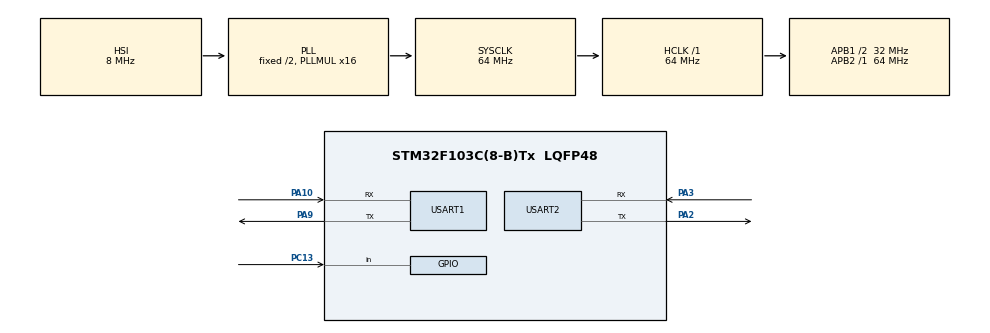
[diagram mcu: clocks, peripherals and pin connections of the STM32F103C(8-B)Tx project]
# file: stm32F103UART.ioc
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Mcu.Family=STM32F1
Mcu.Name=STM32F103C(8-B)Tx
Mcu.Package=LQFP48
NVIC.PriorityGroup=NVIC_PRIORITYGROUP_4
NVIC.USART1_IRQn=true\:0\:0\:false\:false\:true\:true\:true\:true
PA10.Mode=Asynchronous
PA10.Signal=USART1_RX
PA13.Mode=Serial_Wire
PA13.Signal=SYS_JTMS-SWDIO
PA14.Mode=Serial_Wire
PA14.Signal=SYS_JTCK-SWCLK
PA2.Mode=Asynchronous
PA2.Signal=USART2_TX
PA3.Mode=Asynchronous
PA3.Signal=USART2_RX
PA9.Mode=Asynchronous
PA9.Signal=USART1_TX
PC13-TAMPER-RTC.Signal=GPIO_Input
ProjectManager.HeapSize=0x200
ProjectManager.StackSize=0x400
ProjectManager.TargetToolchain=STM32CubeIDE
RCC.AHBFreq_Value=64000000
RCC.APB1CLKDivider=RCC_HCLK_DIV2
RCC.APB1Freq_Value=32000000
RCC.APB1TimFreq_Value=64000000
RCC.APB2Freq_Value=64000000
RCC.APB2TimFreq_Value=64000000
RCC.HCLKFreq_Value=64000000
RCC.PLLMUL=RCC_PLL_MUL16
RCC.SYSCLKFreq_VALUE=64000000
RCC.SYSCLKSource=RCC_SYSCLKSOURCE_PLLCLK
RCC.USBFreq_Value=64000000
USART1.VirtualMode=VM_ASYNC
USART2.VirtualMode=VM_ASYNC
board=custom

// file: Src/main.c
/* USER CODE BEGIN Header */
/**
  ******************************************************************************
  * @file           : main.c
  * @brief          : Main program body
  ******************************************************************************
  * @attention
  *
  * Copyright (c) 2023 STMicroelectronics.
  * All rights reserved.
  *
  * This software is licensed under terms that can be found in the LICENSE file
  * in the root directory of this software component.
  * If no LICENSE file comes with this software, it is provided AS-IS.
  *
  ******************************************************************************
  */

/* USER CODE END Header */
#include "main.h"

/* USER CODE BEGIN PTD */

#define BUFFER_SIZE 16

uint8_t buffer[BUFFER_SIZE] = {0,};
ring_buffer_t rx_buffer;

/* USER CODE END PTD */

UART_HandleTypeDef huart1;
UART_HandleTypeDef huart2;

void SystemClock_Config(void);
static void MX_GPIO_Init(void);
static void MX_USART1_UART_Init(void);
static void MX_USART2_UART_Init(void);

/* USER CODE BEGIN 0 */
/**
 * @brief processing interrupts to receive data
 */

/* USER CODE END 0 */

int main(void)
{

  /* MCU Configuration--------------------------------------------------------*/

  /* Reset of all peripherals, Initializes the Flash interface and the Systick. */
  HAL_Init();

  /* Configure the system clock */
  SystemClock_Config();

  /* Initialize all configured peripherals */
  MX_GPIO_Init();
  MX_USART1_UART_Init();
  MX_USART2_UART_Init();

  /* Infinite loop */
  /* USER CODE BEGIN WHILE */
    ring_buffer_init(buffer, BUFFER_SIZE, &rx_buffer); /// initialization before processing buffer

    while (1) {

    /* USER CODE END WHILE */

    /* USER CODE BEGIN 3 */
        uint8_t rx_temp_byte;
        HAL_UART_Receive(&huart1, &rx_temp_byte, 1, 1000);
        ring_buffer_put(rx_temp_byte, &rx_buffer);
        uint8_t tx_temp_byte;
        tx_temp_byte = ring_buffer_get(&rx_buffer);
        HAL_UART_Transmit(&huart1, &tx_temp_byte, 1, 1000);

       // HAL_UART_Receive_IT(&huart1, &temp_data, 1);

    }
  /* USER CODE END 3 */
}

void SystemClock_Config(void)
{
  RCC_OscInitTypeDef RCC_OscInitStruct = {0};
  RCC_ClkInitTypeDef RCC_ClkInitStruct = {0};

  /** Initializes the RCC Oscillators according to the specified parameters
  * in the RCC_OscInitTypeDef structure.
  */
  RCC_OscInitStruct.OscillatorType = RCC_OSCILLATORTYPE_HSI;
  RCC_OscInitStruct.HSIState = RCC_HSI_ON;
  RCC_OscInitStruct.HSICalibrationValue = RCC_HSICALIBRATION_DEFAULT;
  RCC_OscInitStruct.PLL.PLLState = RCC_PLL_ON;
  RCC_OscInitStruct.PLL.PLLSource = RCC_PLLSOURCE_HSI_DIV2;
  RCC_OscInitStruct.PLL.PLLMUL = RCC_PLL_MUL16;
  if (HAL_RCC_OscConfig(&RCC_OscInitStruct) != HAL_OK)
  {
    Error_Handler();
  }

  /** Initializes the CPU, AHB and APB buses clocks
  */
  RCC_ClkInitStruct.ClockType = RCC_CLOCKTYPE_HCLK|RCC_CLOCKTYPE_SYSCLK
                              |RCC_CLOCKTYPE_PCLK1|RCC_CLOCKTYPE_PCLK2;
  RCC_ClkInitStruct.SYSCLKSource = RCC_SYSCLKSOURCE_PLLCLK;
  RCC_ClkInitStruct.AHBCLKDivider = RCC_SYSCLK_DIV1;
  RCC_ClkInitStruct.APB1CLKDivider = RCC_HCLK_DIV2;
  RCC_ClkInitStruct.APB2CLKDivider = RCC_HCLK_DIV1;

  if (HAL_RCC_ClockConfig(&RCC_ClkInitStruct, FLASH_LATENCY_2) != HAL_OK)
  {
    Error_Handler();
  }
}

static void MX_USART1_UART_Init(void)
{

  huart1.Instance = USART1;
  huart1.Init.BaudRate = 115200;
  huart1.Init.WordLength = UART_WORDLENGTH_8B;
  huart1.Init.StopBits = UART_STOPBITS_1;
  huart1.Init.Parity = UART_PARITY_NONE;
  huart1.Init.Mode = UART_MODE_TX_RX;
  huart1.Init.HwFlowCtl = UART_HWCONTROL_NONE;
  huart1.Init.OverSampling = UART_OVERSAMPLING_16;
  if (HAL_UART_Init(&huart1) != HAL_OK)
  {
    Error_Handler();
  }

}

static void MX_USART2_UART_Init(void)
{

  huart2.Instance = USART2;
  huart2.Init.BaudRate = 115200;
  huart2.Init.WordLength = UART_WORDLENGTH_8B;
  huart2.Init.StopBits = UART_STOPBITS_1;
  huart2.Init.Parity = UART_PARITY_NONE;
  huart2.Init.Mode = UART_MODE_TX_RX;
  huart2.Init.HwFlowCtl = UART_HWCONTROL_NONE;
  huart2.Init.OverSampling = UART_OVERSAMPLING_16;
  if (HAL_UART_Init(&huart2) != HAL_OK)
  {
    Error_Handler();
  }

}

static void MX_GPIO_Init(void)
{
  GPIO_InitTypeDef GPIO_InitStruct = {0};

  /* GPIO Ports Clock Enable */
  __HAL_RCC_GPIOC_CLK_ENABLE();
  __HAL_RCC_GPIOA_CLK_ENABLE();

  /*Configure GPIO pin : PC13 */
  GPIO_InitStruct.Pin = GPIO_PIN_13;
  GPIO_InitStruct.Mode = GPIO_MODE_INPUT;
  GPIO_InitStruct.Pull = GPIO_NOPULL;
  HAL_GPIO_Init(GPIOC, &GPIO_InitStruct);

}

void Error_Handler(void)
{
    __disable_irq();
    while (1) {
    }
}
